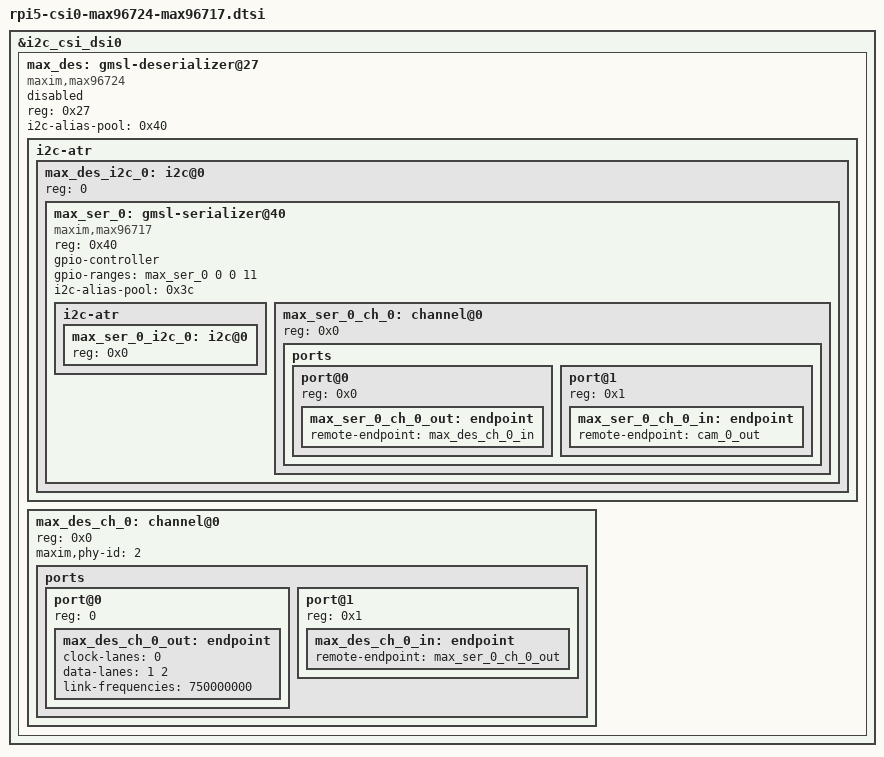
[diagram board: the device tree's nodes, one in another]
&i2c_csi_dsi0 {
	max_des: gmsl-deserializer@27 {
		#address-cells = <1>;
		#size-cells = <0>;

		compatible = "maxim,max96724";
		reg = <0x27>;
		status = "disabled";
	};
};

&max_des {
	i2c-alias-pool = <0x40>;

	i2c-atr {
		#address-cells = <1>;
		#size-cells = <0>;

		max_des_i2c_0: i2c@0 {
			#address-cells = <1>;
			#size-cells = <0>;
			reg = <0>;
		};
	};
};

&max_des {
	max_des_ch_0: channel@0 {
		#address-cells = <1>;
		#size-cells = <0>;

		reg = <0x0>;
	};
};

&max_des_ch_0 {
	maxim,phy-id = <2>;
};

&max_des_ch_0 {
	ports {
		#address-cells = <1>;
		#size-cells = <0>;

		port@0 {
			reg = <0>;

			max_des_ch_0_out: endpoint {
				clock-lanes = <0>;
				data-lanes = <1 2>;
				link-frequencies = /bits/ 64 <750000000>;
			};
		};

		port@1 {
			reg = <0x1>;

			max_des_ch_0_in: endpoint {
				remote-endpoint = <&max_ser_0_ch_0_out>;
			};
		};
	};
};

&max_des_i2c_0 {
	max_ser_0: gmsl-serializer@40 {
		#address-cells = <1>;
		#size-cells = <0>;
		#gpio-cells = <2>;

		compatible = "maxim,max96717";
		reg = <0x40>;

		gpio-controller;
		gpio-ranges = <&max_ser_0 0 0 11>;
	};
};

&max_ser_0 {
	i2c-alias-pool = <0x3c>;

	i2c-atr {
		#address-cells = <1>;
		#size-cells = <0>;

		max_ser_0_i2c_0: i2c@0 {
			#address-cells = <1>;
			#size-cells = <0>;

			reg = <0x0>;
		};
	};
};

&max_ser_0 {
	max_ser_0_ch_0: channel@0 {
		#address-cells = <1>;
		#size-cells = <0>;

		reg = <0x0>;
	};
};

&max_ser_0_ch_0 {
	ports {
		#address-cells = <1>;
		#size-cells = <0>;

		port@0 {
			reg = <0x0>;

			max_ser_0_ch_0_out: endpoint {
				remote-endpoint = <&max_des_ch_0_in>;
			};
		};

		port@1 {
			reg = <0x1>;

			max_ser_0_ch_0_in: endpoint {
				remote-endpoint = <&cam_0_out>;
			};
		};
	};
};
